# SWM231 register map
File version: 1.0
SWM231 Microcontroller registers
CPU: CM0 r1p0, little endian, 2 interrupt priority bits
Registers are 32-bit, read-write, no defined reset value unless marked. A register's access mark holds for its fields unless they carry their own. Offsets are from the block's base; lines under a group give offsets from that group; [hi:lo] are bit positions; {n}, {i} and the like mark numbered series; 'fields as' and 'values as' point back to an identical list; <NAME> marks a mode.

## Memory map
0x40000000 SYS size 0x44854 — Registers group
0x40000800 DMA size 0x30 — Registers group
0x40001800 DIV size 0x20 — Registers group
0x40002000 GPIOA size 0x80 — Registers group
0x40002800 GPIOB size 0x80
0x40040000 UART0 size 0x20 — Registers group
0x40040800 UART1 size 0x20
0x40041000 SPI0 size 0x18 — Registers group
0x40041800 PWM0 size 0x80 — Registers group
0x40041880 PWM1 size 0x80
0x40041C00 PWMG size 0x2C — Registers group
0x40042000 TIMR0 size 0x34 — Registers group
0x40042400 TIMRG size 0x68 — Registers group
0x40042800 BTIMR0 size 0x34
0x40042840 BTIMR1 size 0x34
0x40042880 BTIMR2 size 0x34
0x40042C00 BTIMRG size 0x68
0x40043000 FOC size 0x100 — Registers group
0x40043800 ADC0 size 0x204 — Registers group
0x40044000 FMC size 0x2C — Registers group
0x40045000 PORTA size 0x404 — Registers group
0x40045010 PORTB size 0x404
0x40045800 WDT size 0x14 — Registers group

## SYS — Registers group
Base 0x40000000
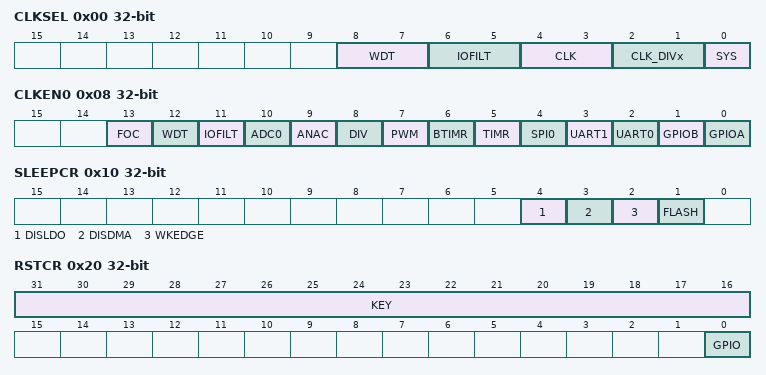
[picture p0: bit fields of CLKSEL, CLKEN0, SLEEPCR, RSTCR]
0x00 CLKSEL
  [8:7] WDT, [6:5] IOFILT, [4:3] CLK, [2:1] CLK_DIVx, [0] SYS
0x04 CLKDIVx_ON
0x08 CLKEN0
  [13] FOC, [12] WDT, [11] IOFILT, [10] ADC0, [9] ANAC, [8] DIV, [7] PWM, [6] BTIMR, [5] TIMR, [4] SPI0, [3] UART1, [2] UART0, [1] GPIOB, [0] GPIOA
0x10 SLEEPCR
  [4] DISLDO, [3] DISDMA, [2] WKEDGE, [1] FLASH
0x20 RSTCR
  [31:16] KEY, [0] GPIO
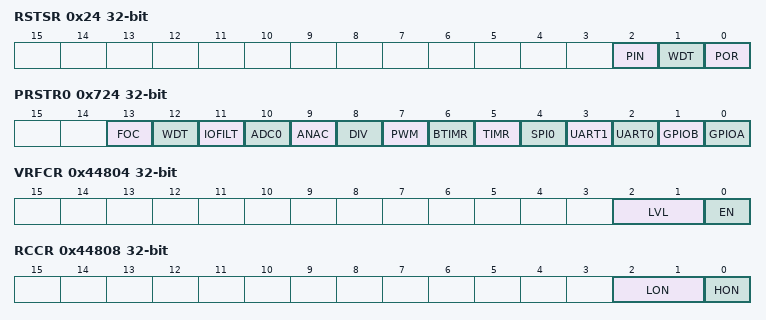
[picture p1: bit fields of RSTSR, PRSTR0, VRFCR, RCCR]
0x24 RSTSR
  [2] PIN, [1] WDT, [0] POR
{0x80+4i} CHIPID[{i}] (i=0..3) ro
{0x90+4i} BACKUP[{i}] (i=0..5)
0x100 PAWKEN
0x104 PBWKEN
0x130 PAWKSR
0x134 PBWKSR
0x400 IOFILT0
0x404 IOFILT1
0x720 PRSTEN
0x724 PRSTR0
  fields as CLKEN0
0x44800 PMUCR
0x44804 VRFCR
  [2:1] LVL, [0] EN
0x44808 RCCR
  [2:1] LON, [0] HON
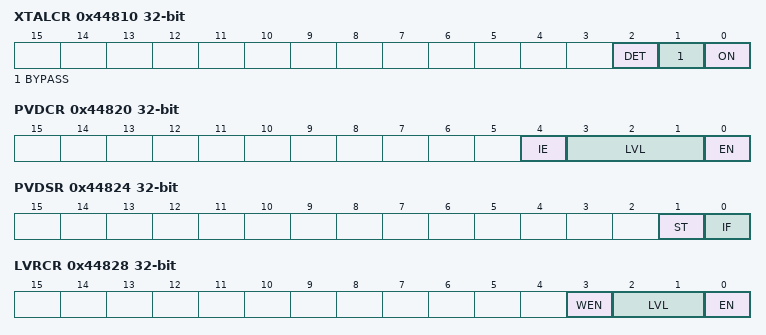
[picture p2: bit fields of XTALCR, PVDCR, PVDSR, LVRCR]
0x44810 XTALCR
  [2] DET, [1] BYPASS, [0] ON
0x44814 XTALSR
  [0] STOP
0x44820 PVDCR
  [4] IE, [3:1] LVL, [0] EN
0x44824 PVDSR
  [1] ST, [0] IF
0x44828 LVRCR
  [3] WEN, [2:1] LVL, [0] EN
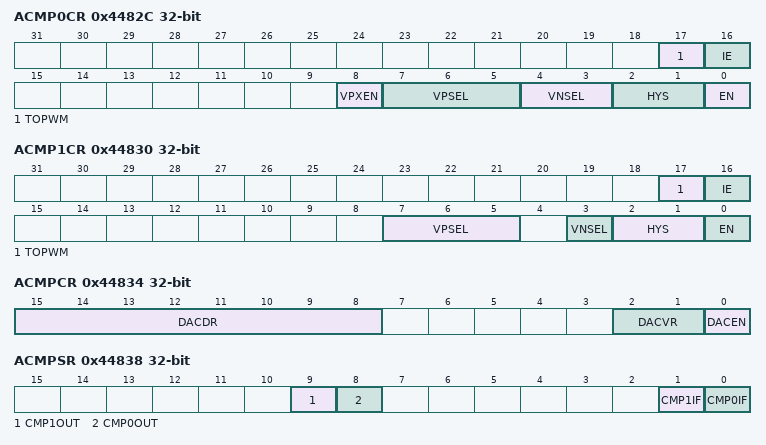
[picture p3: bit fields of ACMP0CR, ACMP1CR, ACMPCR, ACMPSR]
0x4482C ACMP0CR
  [17] TOPWM, [16] IE, [8] VPXEN, [7:5] VPSEL, [4:3] VNSEL, [2:1] HYS, [0] EN
0x44830 ACMP1CR
  [17] TOPWM, [16] IE, [7:5] VPSEL, [3] VNSEL, [2:1] HYS, [0] EN
0x44834 ACMPCR
  [15:8] DACDR, [2:1] DACVR, [0] DACEN
0x44838 ACMPSR
  [9] CMP1OUT, [8] CMP0OUT, [1] CMP1IF, [0] CMP0IF
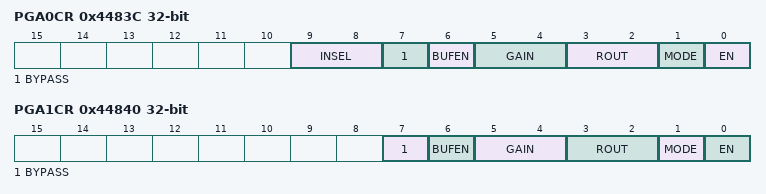
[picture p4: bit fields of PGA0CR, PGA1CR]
0x4483C PGA0CR
  [9:8] INSEL, [7] BYPASS, [6] BUFEN, [5:4] GAIN, [3:2] ROUT, [1] MODE, [0] EN
0x44840 PGA1CR
  [7] BYPASS, [6] BUFEN, [5:4] GAIN, [3:2] ROUT, [1] MODE, [0] EN
0x44848 PGAREF
  [1:0] REFSEL
0x4484C TEMPCR
  [0] EN
0x44850 ADCREF
  [0] REFSEL

## PORTA — Registers group
Base 0x40045000
Same registers: PORTB 0x40045010
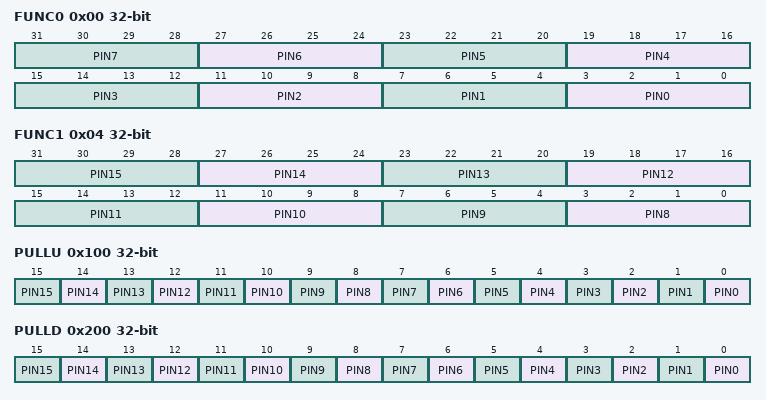
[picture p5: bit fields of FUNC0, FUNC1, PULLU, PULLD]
0x00 FUNC0
  [4n+3:4n] PIN{n} (n=0..7)
0x04 FUNC1
  [4n-29:4n-32] PIN{n} (n=8..15)
0x100 PULLU
  [n] PIN{n} (n=0..15)
0x200 PULLD
  [n] PIN{n} (n=0..15)
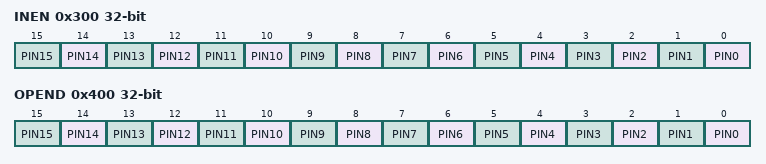
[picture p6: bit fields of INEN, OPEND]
0x300 INEN
  [n] PIN{n} (n=0..15)
0x400 OPEND
  [n] PIN{n} (n=0..15)

## GPIOA — Registers group
Base 0x40002000
Same registers: GPIOB 0x40002800
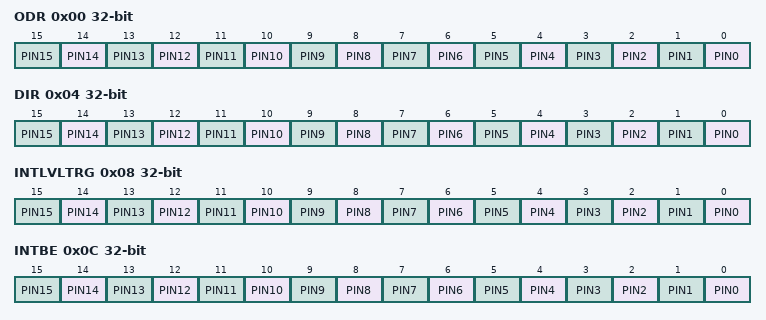
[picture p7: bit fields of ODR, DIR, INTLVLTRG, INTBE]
0x00 ODR
  [n] PIN{n} (n=0..15)
0x04 DIR
  [n] PIN{n} (n=0..15)
0x08 INTLVLTRG
  [n] PIN{n} (n=0..15)
0x0C INTBE
  [n] PIN{n} (n=0..15)
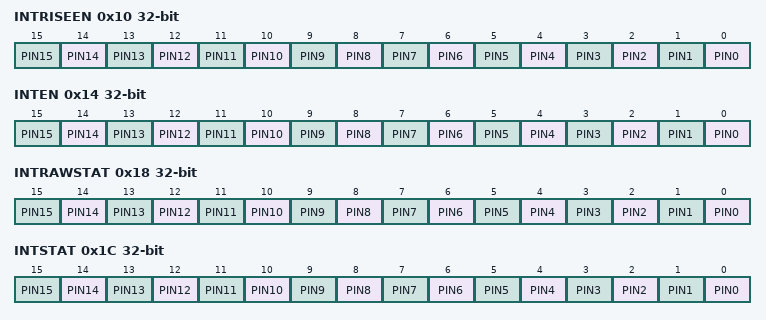
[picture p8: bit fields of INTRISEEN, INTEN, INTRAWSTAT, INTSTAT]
0x10 INTRISEEN
  [n] PIN{n} (n=0..15)
0x14 INTEN
  [n] PIN{n} (n=0..15)
0x18 INTRAWSTAT ro
  [n] PIN{n} (n=0..15)
0x1C INTSTAT ro
  [n] PIN{n} (n=0..15)
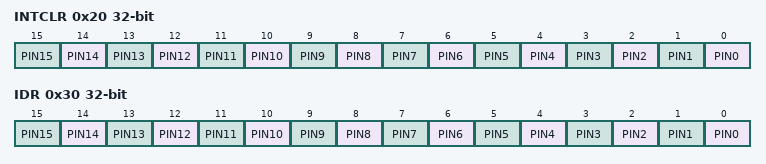
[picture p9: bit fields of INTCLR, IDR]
0x20 INTCLR wo
  [n] PIN{n} (n=0..15)
0x30 IDR ro
  [n] PIN{n} (n=0..15)
{0x40+4i} DATAPIN{i} (i=0..15)

## TIMR0 — Registers group
Base 0x40042000
Same registers: BTIMR0 0x40042800, BTIMR1 0x40042840, BTIMR2 0x40042880
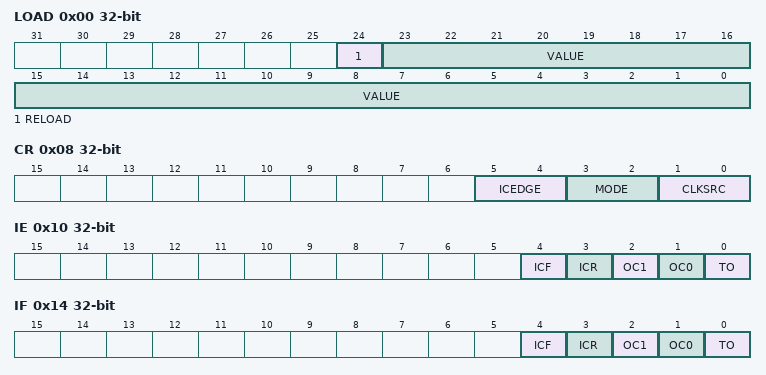
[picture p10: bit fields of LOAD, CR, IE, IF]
0x00 LOAD
  [24] RELOAD, [23:0] VALUE
0x04 VALUE ro
0x08 CR
  [5:4] ICEDGE, [3:2] MODE, [1:0] CLKSRC
0x10 IE
  [4] ICF, [3] ICR, [2] OC1, [1] OC0, [0] TO
0x14 IF
  [4] ICF, [3] ICR, [2] OC1, [1] OC0, [0] TO
0x18 HALT
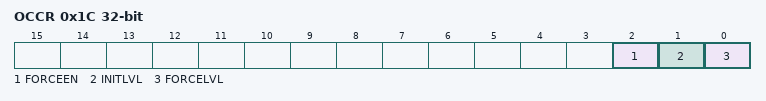
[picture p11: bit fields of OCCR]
0x1C OCCR
  [2] FORCEEN, [1] INITLVL, [0] FORCELVL
0x20 OCMAT
0x28 ICLOW
0x2C ICHIGH
0x30 PREDIV
